# CEC1702 register map
Vendor: Microchip Technology; Series: CEC1702Q; File version: 0
CPU: CM4 r1p0, little endian, MPU, FPU, 3 interrupt priority bits, 155 interrupts
Registers are 32-bit, read-write, reset 0x0 unless marked. A register's access mark holds for its fields unless they carry their own. Offsets are from the block's base; [hi:lo] are bit positions; {n}, {i} and the like mark numbered series.

## HTM0 — The Hibernation Timer can generate a wake event to the Embedded Controller (EC) when it is in a hibernation mode. This block supports wake events up to 2 hours in duration. The timer is a 16-bit binary count-down timer that can be programmed in 30.5us and 0.125 second increments for period ranges of 30.5us to 2s or 0.125s to 136.5 minutes, respectively.
Base 0x40009800; register names take the prefix HTM_
Same registers: HTM1 0x40009820
0x00 PRLD 16-bit — [15:0] This register is used to set the Hibernation Timer Preload value.
0x04 CTRL 16-bit — HTimer Control Register
  [0] CTRL — 1= The Hibernation Timer has a resolution of 0.125s per LSB, which yields a maximum time in excess of 2 hours. 0= The Hibernation Timer has a resolution of 30.5us per LSB, which yields a maximum time of ~2seconds.
0x08 CNT 16-bit ro — The current state of the Hibernation Timer.

## RTOS — The RTOS Timer is a low-power, 32-bit timer designed to operate on the 32kHz oscillator which is available during all chip sleep states. This allows firmware the option to sleep the processor, enter heavy or deep chip sleep states, and wake after a programmed amount of time. The timer may be used as a one-shot timer or a continuous timer. When the timer transitions to 0 it is capable of generating a wake-capable interrupt to the embedded controller. This timer may be halted during debug by hardware or via a software control bit.
Base 0x40007400; register names take the prefix RTOS_
0x00 CNT — RTOS Timer Count Register.
  [31:0] CNTR — This register contains the current value of the RTOS Timer counter. This register should be read as a DWORD. There is no latching mechanism of the upper bytes implemented if the register is accessed as a byte or word. Reading the register with byte or word operations may give incorrect results.
0x04 PRLD — RTOS Timer Preload Register
  [31:0] PRELOAD — The this register is loaded into the RTOS Timer counter either when the TIMER_START bit is written with a 1, or when the timer counter counts down to 0 and the AUTO_RELOAD bit is 1. This register must be programmed with a new count value before the TIMER_START bit is set to 1. If this register is updated while the counter is operating, the new count value will only take effect if the counter transitions form 1 to 0 while the AUTO_RELOAD bit is set.
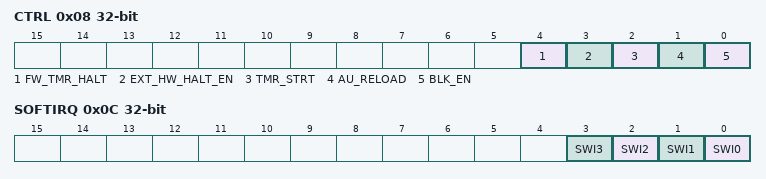
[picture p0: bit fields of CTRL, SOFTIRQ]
0x08 CTRL — RTOS Timer Control Register
  [4] FW_TMR_HALT — 1=The timer counter is halted. If the counter was running, clearing this bit will restart the counter from the value at which it halted. 0=The timer counter, if enabled, will continue to run
  [3] EXT_HW_HALT_EN — 1=The timer counter is halted when the external HALT signal is asserted. Counting is always enabled if HALT is de-asserted. 0=The HALT signal does not affect the RTOS Timer
  [2] TMR_STRT — Writing a 1 to this bit will load the timer counter with the RTOS Timer Preload Register and start counting. If the Preload Register is 0, counting will not start and this bit will be cleared to 0. Writing a 0 to this bit will halt the counter and clear its contents to 0. The RTOS timer interrupt will not be generated. This bit is automatically cleared if the AUTO_RELOAD bit is 0 and the timer counter transitions from 1 to 0.
  [1] AU_RELOAD — 1=The the RTOS Timer Preload Register is loaded into the timer counter and the counter is restarted when the counter transitions from 1 to 0. 0=The timer counter halts when it transitions from 1 to 0 and will not restart.
  [0] BLK_EN — 1=RTOS timer counter is enabled. 0=RTOS timer disabled. All register bits are reset to their default state
0x0C SOFTIRQ wo — Soft Interrupt Register
  [n] SWI{n} (n=0..3) — Software Interrupt. A write of a '1' to this bit will generate an SWI interrupt to the EC. Writes of a '0' have no effect. Reads return '0'.
